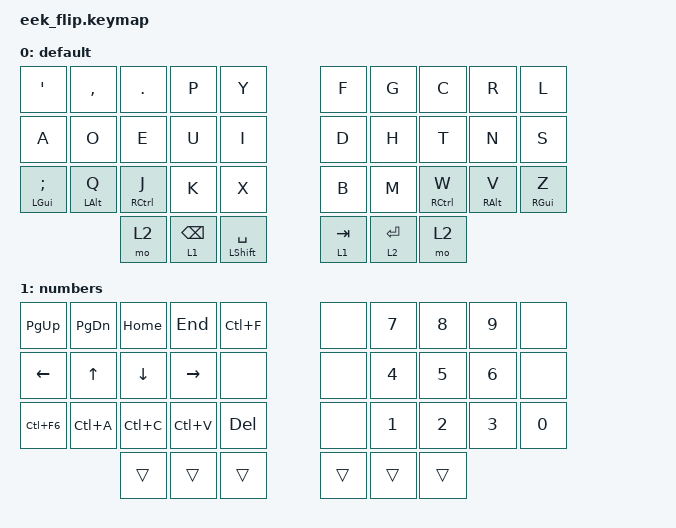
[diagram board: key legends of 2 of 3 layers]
/*
 * Copyright (c) 2020 The ZMK Contributors
 *
 * SPDX-License-Identifier: MIT
 */

#define DEFAULT 0
#define NUMB   1
#define SYMB   2
#define FUNC   3
#define MDIA   4

#include <behaviors.dtsi>
#include <dt-bindings/zmk/keys.h>
#include <dt-bindings/zmk/bt.h>
#include <dt-bindings/zmk/outputs.h>

/ {
    combos {
        compatible = "zmk,combos";
        cexclaim {
            timeout-ms = <50>;
            key-positions = <2 3>;
            bindings = <&kp EXCL>;
			layers = <DEFAULT>;
        };
        combo_esc {
            timeout-ms = <50>;
            key-positions = <1 10>;
            bindings = <&kp ESC>;
			layers = <DEFAULT>;
        };
        cquestion {
            timeout-ms = <50>;
            key-positions = <1 2>;
            bindings = <&kp QMARK>;
			layers = <DEFAULT>;
        };
        cpound {
            timeout-ms = <50>;
            key-positions = <2 11>;
            bindings = <&kp HASH>;
			layers = <DEFAULT>;
        };
    };
    behaviors {
        td0: tap_dance_0 {
            compatible = "zmk,behavior-tap-dance";
            label = "TAP_DANCE_0";
            #binding-cells = <0>;
            tapping-term-ms = <200>;
            bindings = <&kp N1>, <&kp N2>, <&kp N3>;
        };
    };
    keymap {
        compatible = "zmk,keymap";

        default {
// --------------------------------------------------------------------------------------------------------------------------------------------------------------------
//  Q    |  W  |  E  |  R  |  T  | |  Y  |  U  |  I  |    O    |  P   | 
//  A    |  S  |  D  |  F  |  G  | |  H  |  J  |  K  |    L    |  ;   | 
// Lsft/Z|  X  |  C  |  V  |  B  | |  N  |  M  |  ,  |    .    |Rsft//| 
//      | LCTL | Bspc/LMOD | SPC | | Del/Num | Ent | Sym |
           bindings = <
            &kp SQT &kp COMMA &kp DOT &kp P &kp Y &kp F &kp G &kp C &kp R &kp L
            &kp A &kp O &kp E &kp U &kp I &kp D &kp H &kp T &kp N &kp S
            &mt LGUI SEMI &mt LALT Q &mt RCTRL J &kp K &kp X &kp B &kp M &mt RCTRL W &mt RALT V &mt RGUI Z
            &mo 2 &lt 1 BSPC &mt LSHIFT SPACE &lt 1 TAB &lt 2 RET &mo 2
            >;
        };
        numbers {
// --------------------------------------------------------------------------------------------------------------------------------------------------------------------
//  1  |    2   |  3     |  4  |  5  | |  6  |  7  |  8  |  9  |  0  |  
// TAB | BT_PRV | BT_NXT | VOL-| VOL+| |  <  |  v  |  ∧  |  >  |  '  |
// Lsft| BT_SEL0| BT_CLR | MUTE|     | | HOME| END | PGUP| PGDN| Rsft|
//               | LCTL | LMOD| LALT | | Num |     | BL-reset |
           bindings = <
            &kp PG_UP  &kp PG_DN &kp HOME  &kp END   &kp LC(F) &none  &kp N7 &kp N8 &kp N9 &none
            &kp LEFT   &kp UP    &kp DOWN  &kp RIGHT &none     &none  &kp N4 &kp N5 &kp N6 &none
            &kp LC(F6) &kp LC(A) &kp LC(C) &kp LC(V) &kp DEL   &none  &kp N1 &kp N2 &kp N3 &kp N0
                                 &trans    &trans    &trans    &trans &trans &trans
            >;
        };
        symbols {
// --------------------------------------------------------------------------------------------------------------------------------------------------------------------
// ESC |  F1 |  F2 |  F3 |  F4 | | OUT_USB | OUT_BLE |        |  =  |  -   | 
// CAPS|  F5 |  F6 |  F7 |  F8 | |    [    |    ]    |        |  `  |  \   | 
// LSFT|  F9 | F10 | F11 | F12 | |         |         |        |     | RSFT |
//         | LCTL | LMOD| LALT | |  RESET  |         |   SYM  |
           bindings = <
            &kp ESC &kp F1 &kp F2 &kp F3 &kp F4 &out OUT_USB &out OUT_BLE &none  &kp EQUAL &kp MINUS
            &kp CAPS &kp F5 &kp F6 &kp F7 &kp F8 &kp LBKT &kp RBKT &none &kp GRAVE &kp BSLH
            &kp LSHFT &kp F9 &kp F10 &kp F11 &kp F12 &none &none &none &kp RSHFT
            &kp LCTRL &kp LGUI &kp LALT &reset &none &trans
           >;
        };
    };
};
